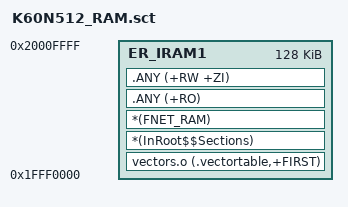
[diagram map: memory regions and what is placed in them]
; *************************************************************
; *** Scatter-Loading Description File generated by uVision ***
; *************************************************************

LR_IRAM1 0x1FFF0000 0x00020000
{ 
    ER_IRAM1 0x1FFF0000 0x00020000  
    {  
        vectors.o (.vectortable,+FIRST)   ; RAM Vector Table
        *(InRoot$$Sections)
        *(FNET_RAM)                            ; FNET Flash driver inram function
       .ANY (+RO)
	   .ANY (+RW +ZI)
    }
}

